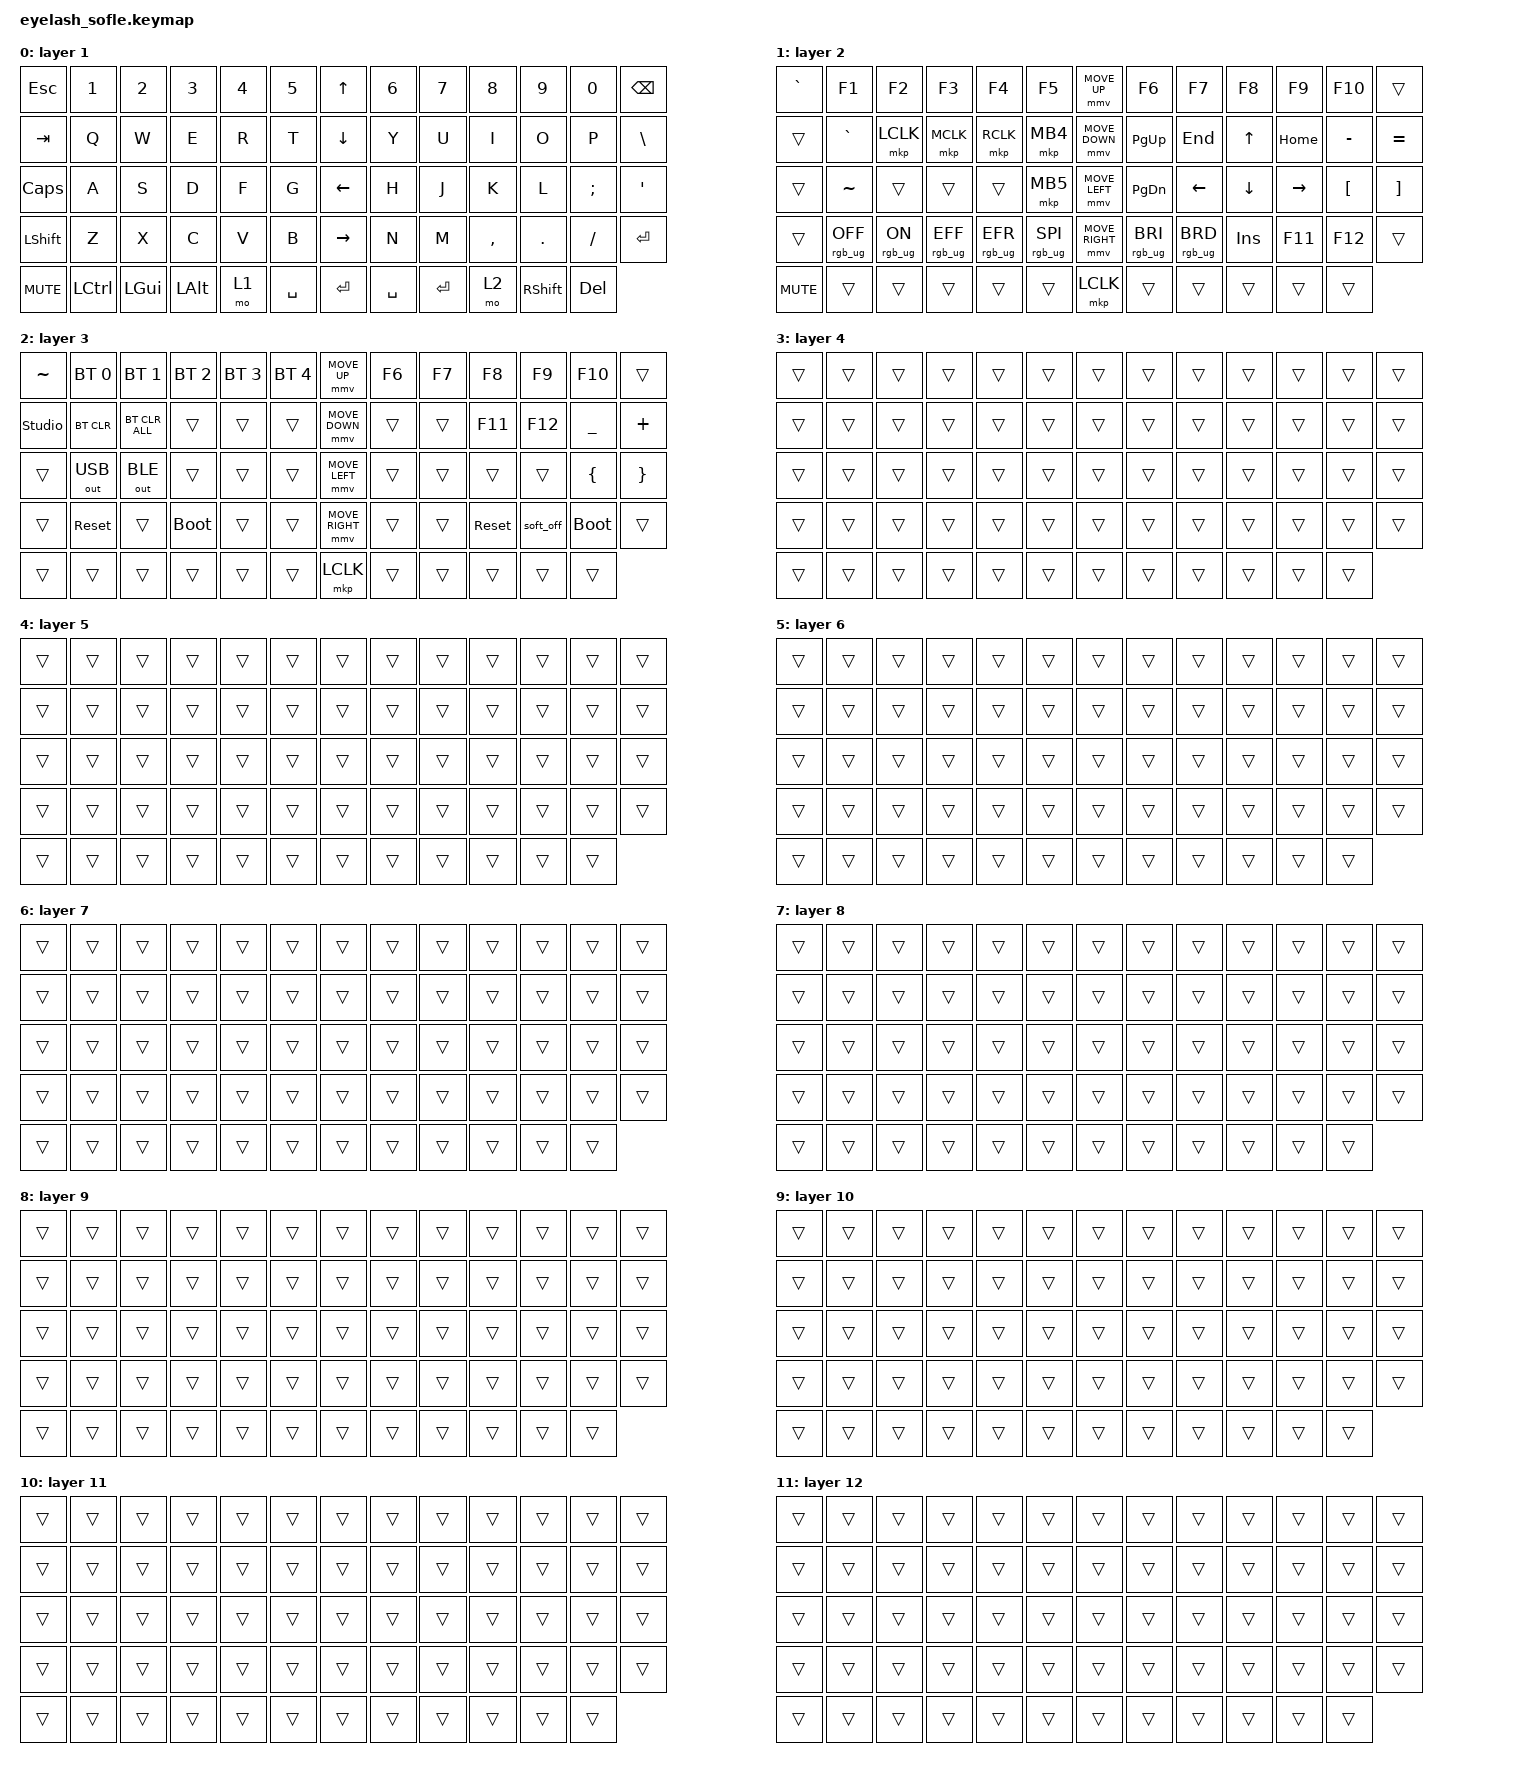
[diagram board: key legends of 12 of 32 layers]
#include <behaviors.dtsi>
#include <dt-bindings/zmk/bt.h>
#include <dt-bindings/zmk/keys.h>
#include <dt-bindings/zmk/mouse.h>
#include <dt-bindings/zmk/outputs.h>
#include <dt-bindings/zmk/rgb.h>

#include <input/processors.dtsi>

/*

   &mmv_input_listener {
       input-processors = <&zip_xy_scaler 2 1>;
   };

   &msc_input_listener {
       input-processors = <&zip_xy_scaler 2 1>;
   };

 */

#define ZMK_MOUSE_DEFAULT_MOVE_VAL 1200  // 600
#define ZMK_MOUSE_DEFAULT_SCRL_VAL 20    // 10


/ {
    behaviors {
        mmv {
            acceleration-exponent = <1>;      // 1
            time-to-max-speed-ms = <900>;    // 40
            delay-ms = <0>;                   // 0
        };

        msc {
            acceleration-exponent = <1>;      // 0
            time-to-max-speed-ms = <400>;      // 500
            delay-ms = <0>;                   //   10
        };
    };

    scroll_encoder: scroll_encoder {
        compatible = "zmk,behavior-sensor-rotate";
        #sensor-binding-cells = <0>;
        bindings = <&msc SCRL_DOWN>, <&msc SCRL_UP>;

        tap-ms = <30>;
    };

    keymap {
        compatible = "zmk,keymap";

        layer0 {
            bindings = <
&kp ESC     &kp N1     &kp N2        &kp N3        &kp N4  &kp N5       &kp UP_ARROW     &kp N6     &kp N7     &kp N8     &kp N9           &kp N0      &kp BACKSPACE
&kp TAB     &kp Q      &kp W         &kp E         &kp R   &kp T        &kp DOWN_ARROW   &kp Y      &kp U      &kp I      &kp O            &kp P       &kp BSLH
&kp CAPS    &kp A      &kp S         &kp D         &kp F   &kp G        &kp LEFT_ARROW   &kp H      &kp J      &kp K      &kp L            &kp SEMI    &kp APOS
&kp LSHFT   &kp Z      &kp X         &kp C         &kp V   &kp B        &kp RIGHT_ARROW  &kp N      &kp M      &kp COMMA  &kp DOT          &kp FSLH    &kp ENTER
&kp C_MUTE  &kp LCTRL  &kp LEFT_GUI  &kp LEFT_ALT  &mo 1   &kp SPACE    &kp ENTER        &kp SPACE  &kp ENTER  &mo 2      &kp RIGHT_SHIFT  &kp DELETE
            >;

            sensor-bindings = <&inc_dec_kp C_VOLUME_UP C_VOL_DN>;
            display-name = "layer 1";
        };

        layer1 {
            bindings = <
&kp GRAVE   &kp F1           &kp F2          &kp F3           &kp F4           &kp F5             &mmv MOVE_UP     &kp F6           &kp F7           &kp F8      &kp F9     &kp F10           &trans
&trans      &kp GRAVE        &mkp LCLK       &mkp MCLK        &mkp RCLK        &mkp MB4           &mmv MOVE_DOWN   &kp PG_UP        &kp END          &kp UP      &kp HOME   &kp MINUS         &kp EQUAL
&trans      &kp TILDE        &trans          &trans           &trans           &mkp MB5           &mmv MOVE_LEFT   &kp PG_DN        &kp LEFT         &kp DOWN    &kp RIGHT  &kp LEFT_BRACKET  &kp RIGHT_BRACKET
&trans      &rgb_ug RGB_OFF  &rgb_ug RGB_ON  &rgb_ug RGB_EFF  &rgb_ug RGB_EFR  &rgb_ug RGB_SPI    &mmv MOVE_RIGHT  &rgb_ug RGB_BRI  &rgb_ug RGB_BRD  &kp INSERT  &kp F11    &kp F12           &trans
&kp C_MUTE  &trans           &trans          &trans           &trans           &trans             &mkp LCLK        &trans           &trans           &trans      &trans     &trans
            >;

            sensor-bindings = <&scroll_encoder>;
            display-name = "layer 2";
        };

        layer2 {
            bindings = <
&kp TILDE  &bt BT_SEL 0  &bt BT_SEL 1    &bt BT_SEL 2  &bt BT_SEL 3  &bt BT_SEL 4    &mmv MOVE_UP     &kp F6  &kp F7  &kp F8      &kp F9     &kp F10      &trans
&studio_unlock      &bt BT_CLR    &bt BT_CLR_ALL  &trans        &trans        &trans          &mmv MOVE_DOWN   &trans  &trans  &kp F11     &kp F12    &kp UNDER    &kp PLUS
&trans     &out OUT_USB  &out OUT_BLE    &trans        &trans        &trans          &mmv MOVE_LEFT   &trans  &trans  &trans      &trans     &kp LBRC     &kp RBRC
&trans     &sys_reset    &trans          &bootloader   &trans        &trans          &mmv MOVE_RIGHT  &trans  &trans  &sys_reset  &soft_off  &bootloader  &trans
&trans     &trans        &trans          &trans        &trans        &trans          &mkp LCLK        &trans  &trans  &trans      &trans     &trans
            >;

            sensor-bindings = <&scroll_encoder>;
            display-name = "layer 3";
        };

        layer3 {
            bindings = <
&trans &trans &trans &trans &trans &trans &trans &trans &trans &trans &trans &trans &trans
&trans &trans &trans &trans &trans &trans &trans &trans &trans &trans &trans &trans &trans
&trans &trans &trans &trans &trans &trans &trans &trans &trans &trans &trans &trans &trans
&trans &trans &trans &trans &trans &trans &trans &trans &trans &trans &trans &trans &trans
&trans &trans &trans &trans &trans &trans &trans &trans &trans &trans &trans &trans
            >;
            sensor-bindings = <&scroll_encoder>;
            display-name = "layer 4";
        };

        layer4 {
            bindings = <
&trans &trans &trans &trans &trans &trans &trans &trans &trans &trans &trans &trans &trans
&trans &trans &trans &trans &trans &trans &trans &trans &trans &trans &trans &trans &trans
&trans &trans &trans &trans &trans &trans &trans &trans &trans &trans &trans &trans &trans
&trans &trans &trans &trans &trans &trans &trans &trans &trans &trans &trans &trans &trans
&trans &trans &trans &trans &trans &trans &trans &trans &trans &trans &trans &trans
            >;
            sensor-bindings = <&scroll_encoder>;
            display-name = "layer 5";
        };

        layer5 {
            bindings = <
&trans &trans &trans &trans &trans &trans &trans &trans &trans &trans &trans &trans &trans
&trans &trans &trans &trans &trans &trans &trans &trans &trans &trans &trans &trans &trans
&trans &trans &trans &trans &trans &trans &trans &trans &trans &trans &trans &trans &trans
&trans &trans &trans &trans &trans &trans &trans &trans &trans &trans &trans &trans &trans
&trans &trans &trans &trans &trans &trans &trans &trans &trans &trans &trans &trans
            >;
            sensor-bindings = <&scroll_encoder>;
            display-name = "layer 6";
        };

        layer6 {
            bindings = <
&trans &trans &trans &trans &trans &trans &trans &trans &trans &trans &trans &trans &trans
&trans &trans &trans &trans &trans &trans &trans &trans &trans &trans &trans &trans &trans
&trans &trans &trans &trans &trans &trans &trans &trans &trans &trans &trans &trans &trans
&trans &trans &trans &trans &trans &trans &trans &trans &trans &trans &trans &trans &trans
&trans &trans &trans &trans &trans &trans &trans &trans &trans &trans &trans &trans
            >;
            sensor-bindings = <&scroll_encoder>;
            display-name = "layer 7";
        };

        layer7 {
            bindings = <
&trans &trans &trans &trans &trans &trans &trans &trans &trans &trans &trans &trans &trans
&trans &trans &trans &trans &trans &trans &trans &trans &trans &trans &trans &trans &trans
&trans &trans &trans &trans &trans &trans &trans &trans &trans &trans &trans &trans &trans
&trans &trans &trans &trans &trans &trans &trans &trans &trans &trans &trans &trans &trans
&trans &trans &trans &trans &trans &trans &trans &trans &trans &trans &trans &trans
            >;
            sensor-bindings = <&scroll_encoder>;
            display-name = "layer 8";
        };

        layer8 {
            bindings = <
&trans &trans &trans &trans &trans &trans &trans &trans &trans &trans &trans &trans &trans
&trans &trans &trans &trans &trans &trans &trans &trans &trans &trans &trans &trans &trans
&trans &trans &trans &trans &trans &trans &trans &trans &trans &trans &trans &trans &trans
&trans &trans &trans &trans &trans &trans &trans &trans &trans &trans &trans &trans &trans
&trans &trans &trans &trans &trans &trans &trans &trans &trans &trans &trans &trans
            >;
            sensor-bindings = <&scroll_encoder>;
            display-name = "layer 9";
        };

        layer9 {
            bindings = <
&trans &trans &trans &trans &trans &trans &trans &trans &trans &trans &trans &trans &trans
&trans &trans &trans &trans &trans &trans &trans &trans &trans &trans &trans &trans &trans
&trans &trans &trans &trans &trans &trans &trans &trans &trans &trans &trans &trans &trans
&trans &trans &trans &trans &trans &trans &trans &trans &trans &trans &trans &trans &trans
&trans &trans &trans &trans &trans &trans &trans &trans &trans &trans &trans &trans
            >;
            sensor-bindings = <&scroll_encoder>;
            display-name = "layer 10";
        };

        layer10 {
            bindings = <
&trans &trans &trans &trans &trans &trans &trans &trans &trans &trans &trans &trans &trans
&trans &trans &trans &trans &trans &trans &trans &trans &trans &trans &trans &trans &trans
&trans &trans &trans &trans &trans &trans &trans &trans &trans &trans &trans &trans &trans
&trans &trans &trans &trans &trans &trans &trans &trans &trans &trans &trans &trans &trans
&trans &trans &trans &trans &trans &trans &trans &trans &trans &trans &trans &trans
            >;
            sensor-bindings = <&scroll_encoder>;
            display-name = "layer 11";
        };

        layer11 {
            bindings = <
&trans &trans &trans &trans &trans &trans &trans &trans &trans &trans &trans &trans &trans
&trans &trans &trans &trans &trans &trans &trans &trans &trans &trans &trans &trans &trans
&trans &trans &trans &trans &trans &trans &trans &trans &trans &trans &trans &trans &trans
&trans &trans &trans &trans &trans &trans &trans &trans &trans &trans &trans &trans &trans
&trans &trans &trans &trans &trans &trans &trans &trans &trans &trans &trans &trans
            >;
            sensor-bindings = <&scroll_encoder>;
            display-name = "layer 12";
        };

        layer12 {
            bindings = <
&trans &trans &trans &trans &trans &trans &trans &trans &trans &trans &trans &trans &trans
&trans &trans &trans &trans &trans &trans &trans &trans &trans &trans &trans &trans &trans
&trans &trans &trans &trans &trans &trans &trans &trans &trans &trans &trans &trans &trans
&trans &trans &trans &trans &trans &trans &trans &trans &trans &trans &trans &trans &trans
&trans &trans &trans &trans &trans &trans &trans &trans &trans &trans &trans &trans
            >;
            sensor-bindings = <&scroll_encoder>;
            display-name = "layer 13";
        };

        layer13 {
            bindings = <
&trans &trans &trans &trans &trans &trans &trans &trans &trans &trans &trans &trans &trans
&trans &trans &trans &trans &trans &trans &trans &trans &trans &trans &trans &trans &trans
&trans &trans &trans &trans &trans &trans &trans &trans &trans &trans &trans &trans &trans
&trans &trans &trans &trans &trans &trans &trans &trans &trans &trans &trans &trans &trans
&trans &trans &trans &trans &trans &trans &trans &trans &trans &trans &trans &trans
            >;
            sensor-bindings = <&scroll_encoder>;
            display-name = "layer 14";
        };

        layer14 {
            bindings = <
&trans &trans &trans &trans &trans &trans &trans &trans &trans &trans &trans &trans &trans
&trans &trans &trans &trans &trans &trans &trans &trans &trans &trans &trans &trans &trans
&trans &trans &trans &trans &trans &trans &trans &trans &trans &trans &trans &trans &trans
&trans &trans &trans &trans &trans &trans &trans &trans &trans &trans &trans &trans &trans
&trans &trans &trans &trans &trans &trans &trans &trans &trans &trans &trans &trans
            >;
            sensor-bindings = <&scroll_encoder>;
            display-name = "layer 15";
        };

        layer15 {
            bindings = <
&trans &trans &trans &trans &trans &trans &trans &trans &trans &trans &trans &trans &trans
&trans &trans &trans &trans &trans &trans &trans &trans &trans &trans &trans &trans &trans
&trans &trans &trans &trans &trans &trans &trans &trans &trans &trans &trans &trans &trans
&trans &trans &trans &trans &trans &trans &trans &trans &trans &trans &trans &trans &trans
&trans &trans &trans &trans &trans &trans &trans &trans &trans &trans &trans &trans
            >;
            sensor-bindings = <&scroll_encoder>;
            display-name = "layer 16";
        };

        layer16 {
            bindings = <
&trans &trans &trans &trans &trans &trans &trans &trans &trans &trans &trans &trans &trans
&trans &trans &trans &trans &trans &trans &trans &trans &trans &trans &trans &trans &trans
&trans &trans &trans &trans &trans &trans &trans &trans &trans &trans &trans &trans &trans
&trans &trans &trans &trans &trans &trans &trans &trans &trans &trans &trans &trans &trans
&trans &trans &trans &trans &trans &trans &trans &trans &trans &trans &trans &trans
            >;
            sensor-bindings = <&scroll_encoder>;
            display-name = "layer 17";
        };

        layer17 {
            bindings = <
&trans &trans &trans &trans &trans &trans &trans &trans &trans &trans &trans &trans &trans
&trans &trans &trans &trans &trans &trans &trans &trans &trans &trans &trans &trans &trans
&trans &trans &trans &trans &trans &trans &trans &trans &trans &trans &trans &trans &trans
&trans &trans &trans &trans &trans &trans &trans &trans &trans &trans &trans &trans &trans
&trans &trans &trans &trans &trans &trans &trans &trans &trans &trans &trans &trans
            >;
            sensor-bindings = <&scroll_encoder>;
            display-name = "layer 18";
        };

        layer18 {
            bindings = <
&trans &trans &trans &trans &trans &trans &trans &trans &trans &trans &trans &trans &trans
&trans &trans &trans &trans &trans &trans &trans &trans &trans &trans &trans &trans &trans
&trans &trans &trans &trans &trans &trans &trans &trans &trans &trans &trans &trans &trans
&trans &trans &trans &trans &trans &trans &trans &trans &trans &trans &trans &trans &trans
&trans &trans &trans &trans &trans &trans &trans &trans &trans &trans &trans &trans
            >;
            sensor-bindings = <&scroll_encoder>;
            display-name = "layer 19";
        };

        layer19 {
            bindings = <
&trans &trans &trans &trans &trans &trans &trans &trans &trans &trans &trans &trans &trans
&trans &trans &trans &trans &trans &trans &trans &trans &trans &trans &trans &trans &trans
&trans &trans &trans &trans &trans &trans &trans &trans &trans &trans &trans &trans &trans
&trans &trans &trans &trans &trans &trans &trans &trans &trans &trans &trans &trans &trans
&trans &trans &trans &trans &trans &trans &trans &trans &trans &trans &trans &trans
            >;
            sensor-bindings = <&scroll_encoder>;
            display-name = "layer 20";
        };

        layer20 {
            bindings = <
&trans &trans &trans &trans &trans &trans &trans &trans &trans &trans &trans &trans &trans
&trans &trans &trans &trans &trans &trans &trans &trans &trans &trans &trans &trans &trans
&trans &trans &trans &trans &trans &trans &trans &trans &trans &trans &trans &trans &trans
&trans &trans &trans &trans &trans &trans &trans &trans &trans &trans &trans &trans &trans
&trans &trans &trans &trans &trans &trans &trans &trans &trans &trans &trans &trans
            >;
            sensor-bindings = <&scroll_encoder>;
            display-name = "layer 21";
        };

        layer21 {
            bindings = <
&trans &trans &trans &trans &trans &trans &trans &trans &trans &trans &trans &trans &trans
&trans &trans &trans &trans &trans &trans &trans &trans &trans &trans &trans &trans &trans
&trans &trans &trans &trans &trans &trans &trans &trans &trans &trans &trans &trans &trans
&trans &trans &trans &trans &trans &trans &trans &trans &trans &trans &trans &trans &trans
&trans &trans &trans &trans &trans &trans &trans &trans &trans &trans &trans &trans
            >;
            sensor-bindings = <&scroll_encoder>;
            display-name = "layer 22";
        };

        layer22 {
            bindings = <
&trans &trans &trans &trans &trans &trans &trans &trans &trans &trans &trans &trans &trans
&trans &trans &trans &trans &trans &trans &trans &trans &trans &trans &trans &trans &trans
&trans &trans &trans &trans &trans &trans &trans &trans &trans &trans &trans &trans &trans
&trans &trans &trans &trans &trans &trans &trans &trans &trans &trans &trans &trans &trans
&trans &trans &trans &trans &trans &trans &trans &trans &trans &trans &trans &trans
            >;
            sensor-bindings = <&scroll_encoder>;
            display-name = "layer 23";
        };

        layer23 {
            bindings = <
&trans &trans &trans &trans &trans &trans &trans &trans &trans &trans &trans &trans &trans
&trans &trans &trans &trans &trans &trans &trans &trans &trans &trans &trans &trans &trans
&trans &trans &trans &trans &trans &trans &trans &trans &trans &trans &trans &trans &trans
&trans &trans &trans &trans &trans &trans &trans &trans &trans &trans &trans &trans &trans
&trans &trans &trans &trans &trans &trans &trans &trans &trans &trans &trans &trans
            >;
            sensor-bindings = <&scroll_encoder>;
            display-name = "layer 24";
        };

        layer24 {
            bindings = <
&trans &trans &trans &trans &trans &trans &trans &trans &trans &trans &trans &trans &trans
&trans &trans &trans &trans &trans &trans &trans &trans &trans &trans &trans &trans &trans
&trans &trans &trans &trans &trans &trans &trans &trans &trans &trans &trans &trans &trans
&trans &trans &trans &trans &trans &trans &trans &trans &trans &trans &trans &trans &trans
&trans &trans &trans &trans &trans &trans &trans &trans &trans &trans &trans &trans
            >;
            sensor-bindings = <&scroll_encoder>;
            display-name = "layer 25";
        };

        layer25 {
            bindings = <
&trans &trans &trans &trans &trans &trans &trans &trans &trans &trans &trans &trans &trans
&trans &trans &trans &trans &trans &trans &trans &trans &trans &trans &trans &trans &trans
&trans &trans &trans &trans &trans &trans &trans &trans &trans &trans &trans &trans &trans
&trans &trans &trans &trans &trans &trans &trans &trans &trans &trans &trans &trans &trans
&trans &trans &trans &trans &trans &trans &trans &trans &trans &trans &trans &trans
            >;
            sensor-bindings = <&scroll_encoder>;
            display-name = "layer 26";
        };

        layer26 {
            bindings = <
&trans &trans &trans &trans &trans &trans &trans &trans &trans &trans &trans &trans &trans
&trans &trans &trans &trans &trans &trans &trans &trans &trans &trans &trans &trans &trans
&trans &trans &trans &trans &trans &trans &trans &trans &trans &trans &trans &trans &trans
&trans &trans &trans &trans &trans &trans &trans &trans &trans &trans &trans &trans &trans
&trans &trans &trans &trans &trans &trans &trans &trans &trans &trans &trans &trans
            >;
            sensor-bindings = <&scroll_encoder>;
            display-name = "layer 27";
        };

        layer27 {
            bindings = <
&trans &trans &trans &trans &trans &trans &trans &trans &trans &trans &trans &trans &trans
&trans &trans &trans &trans &trans &trans &trans &trans &trans &trans &trans &trans &trans
&trans &trans &trans &trans &trans &trans &trans &trans &trans &trans &trans &trans &trans
&trans &trans &trans &trans &trans &trans &trans &trans &trans &trans &trans &trans &trans
&trans &trans &trans &trans &trans &trans &trans &trans &trans &trans &trans &trans
            >;
            sensor-bindings = <&scroll_encoder>;
            display-name = "layer 28";
        };

        layer28 {
            bindings = <
&trans &trans &trans &trans &trans &trans &trans &trans &trans &trans &trans &trans &trans
&trans &trans &trans &trans &trans &trans &trans &trans &trans &trans &trans &trans &trans
&trans &trans &trans &trans &trans &trans &trans &trans &trans &trans &trans &trans &trans
&trans &trans &trans &trans &trans &trans &trans &trans &trans &trans &trans &trans &trans
&trans &trans &trans &trans &trans &trans &trans &trans &trans &trans &trans &trans
            >;
            sensor-bindings = <&scroll_encoder>;
            display-name = "layer 29";
        };

        layer29 {
            bindings = <
&trans &trans &trans &trans &trans &trans &trans &trans &trans &trans &trans &trans &trans
&trans &trans &trans &trans &trans &trans &trans &trans &trans &trans &trans &trans &trans
&trans &trans &trans &trans &trans &trans &trans &trans &trans &trans &trans &trans &trans
&trans &trans &trans &trans &trans &trans &trans &trans &trans &trans &trans &trans &trans
&trans &trans &trans &trans &trans &trans &trans &trans &trans &trans &trans &trans
            >;
            sensor-bindings = <&scroll_encoder>;
            display-name = "layer 30";
        };

        layer30 {
            bindings = <
&trans &trans &trans &trans &trans &trans &trans &trans &trans &trans &trans &trans &trans
&trans &trans &trans &trans &trans &trans &trans &trans &trans &trans &trans &trans &trans
&trans &trans &trans &trans &trans &trans &trans &trans &trans &trans &trans &trans &trans
&trans &trans &trans &trans &trans &trans &trans &trans &trans &trans &trans &trans &trans
&trans &trans &trans &trans &trans &trans &trans &trans &trans &trans &trans &trans
            >;
            sensor-bindings = <&scroll_encoder>;
            display-name = "layer 31";
        };

        layer31 {
            bindings = <
&trans &trans &trans &trans &trans &trans &trans &trans &trans &trans &trans &trans &trans
&trans &trans &trans &trans &trans &trans &trans &trans &trans &trans &trans &trans &trans
&trans &trans &trans &trans &trans &trans &trans &trans &trans &trans &trans &trans &trans
&trans &trans &trans &trans &trans &trans &trans &trans &trans &trans &trans &trans &trans
&trans &trans &trans &trans &trans &trans &trans &trans &trans &trans &trans &trans
            >;
            sensor-bindings = <&scroll_encoder>;
            display-name = "layer 32";
        };
    };
};
